# HT32F125x register map
File version: 1.1
This is the description for the Holtek HT32F125x
CPU: CM3 r2p0, little endian, no MPU, no FPU, 4 interrupt priority bits
Registers are 32-bit, read-write, reset 0x0 unless marked. A register's access mark holds for its fields unless they carry their own. Offsets are from the block's base; lines under a group give offsets from that group; [hi:lo] are bit positions; {n}, {i} and the like mark numbered series; 'fields as' and 'values as' point back to an identical list; <NAME> marks a mode.

## Memory map
0x40000000 USART size 0x1000
0x40004000 SPI size 0x1000
0x40010000 ADC size 0x1000
0x40018000 OPACMP size 0x1000
0x4001A000 GPIOA size 0x1000
0x4001B000 GPIOB size 0x1000
0x40022000 AFIO size 0x1000
0x40024000 EXTI size 0x1000
0x40048000 I2C size 0x1000
0x40068000 WDT size 0x1000
0x4006A000 RTC size 0x1000
0x4006A100 PWRCU size 0x1000
0x4006E000 GPTM0 size 0x1000
0x4006F000 GPTM1 size 0x1000
0x40080000 FMC size 0x1000
0x40088000 CKCU size 0x1000
0x40088100 RSTCU size 0x1000
0xE000E000 NVIC size 0x1000
0xE000E010 SysTick size 0x1000
0xE000ED10 SCB size 0x1000
0xE000ED28 Fault_Reports size 0x1000

## Interrupts
0 CKRDY (CKCU)
1 LVD (PWRCU)
2 BOD (PWRCU)
3 WDT
4 RTC
5 FMC
6 EVWUP (EXTI)
7 LPWUP (PWRCU)
{n+8} EXTI{n} (EXTI) (n=0..15)
24 COMP (OPACMP)
25 ADC
35 GPTM0
36 GPTM1
43 I2C
45 SPI
47 USART

## NVIC
Base 0xE000E000
0x04 ICTR
  [4:0] INTLINESNUM
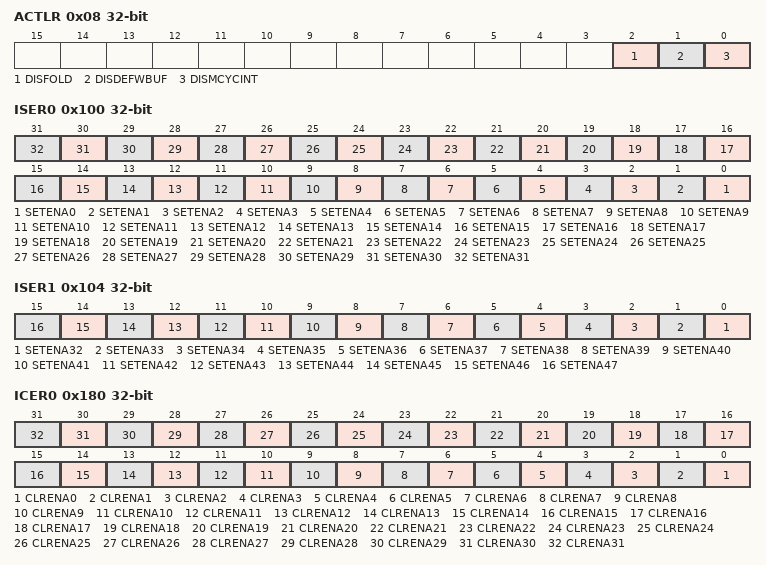
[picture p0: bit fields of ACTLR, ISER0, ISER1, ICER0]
0x08 ACTLR
  [2] DISFOLD, [1] DISDEFWBUF, [0] DISMCYCINT
0x100 ISER0
  [n] SETENA{n} (n=0..31)
0x104 ISER1
  [n-32] SETENA{n} (n=32..47)
0x180 ICER0
  [n] CLRENA{n} (n=0..31)
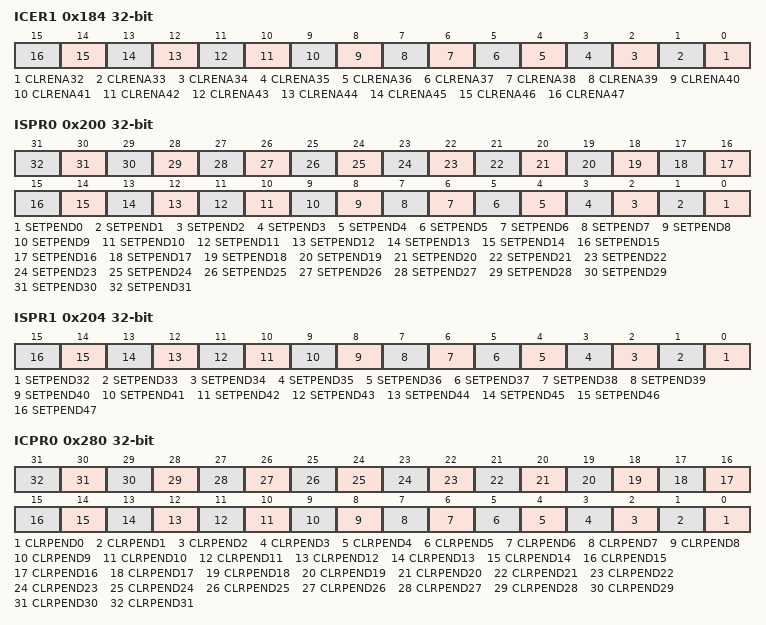
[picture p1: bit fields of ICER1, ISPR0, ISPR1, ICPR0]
0x184 ICER1
  [n-32] CLRENA{n} (n=32..47)
0x200 ISPR0
  [n] SETPEND{n} (n=0..31)
0x204 ISPR1
  [n-32] SETPEND{n} (n=32..47)
0x280 ICPR0
  [n] CLRPEND{n} (n=0..31)
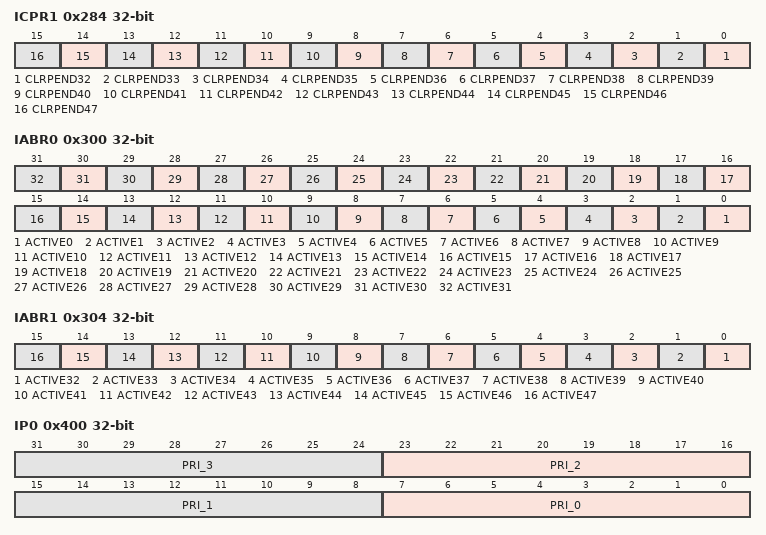
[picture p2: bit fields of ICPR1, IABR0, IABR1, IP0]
0x284 ICPR1
  [n-32] CLRPEND{n} (n=32..47)
0x300 IABR0
  [n] ACTIVE{n} (n=0..31)
0x304 IABR1
  [n-32] ACTIVE{n} (n=32..47)
0x400 IP0
  [8n+7:8n] PRI_{n} (n=0..3)
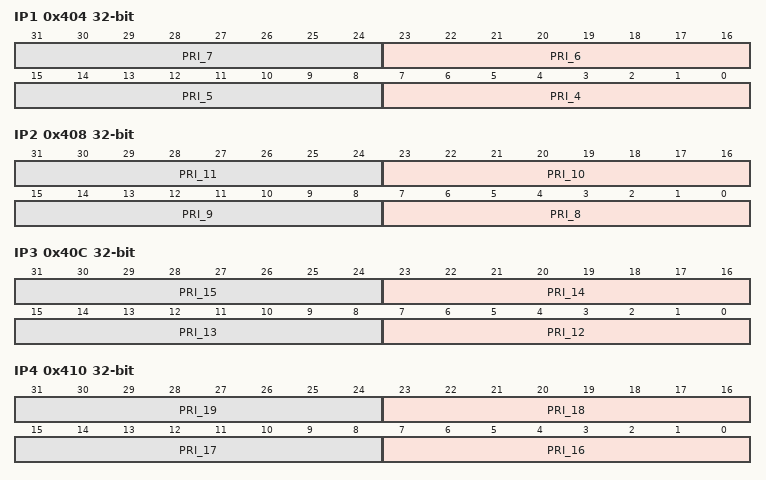
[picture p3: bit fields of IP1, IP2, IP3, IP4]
0x404 IP1
  [8n-25:8n-32] PRI_{n} (n=4..7)
0x408 IP2
  [8n-57:8n-64] PRI_{n} (n=8..11)
0x40C IP3
  [8n-89:8n-96] PRI_{n} (n=12..15)
0x410 IP4
  [8n-121:8n-128] PRI_{n} (n=16..19)
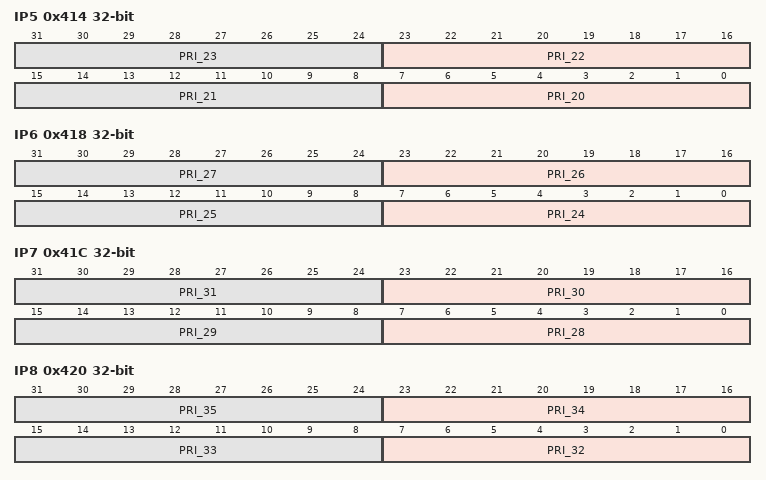
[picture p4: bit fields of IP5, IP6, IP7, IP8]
0x414 IP5
  [8n-153:8n-160] PRI_{n} (n=20..23)
0x418 IP6
  [8n-185:8n-192] PRI_{n} (n=24..27)
0x41C IP7
  [8n-217:8n-224] PRI_{n} (n=28..31)
0x420 IP8
  [8n-249:8n-256] PRI_{n} (n=32..35)
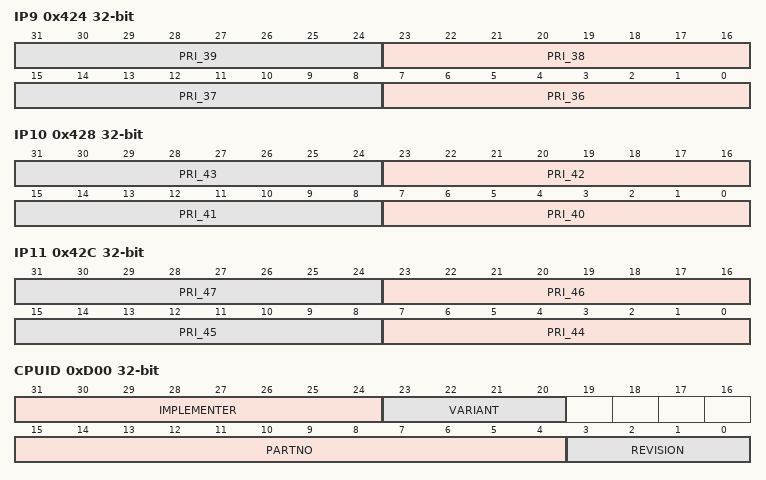
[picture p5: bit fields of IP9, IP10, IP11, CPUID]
0x424 IP9
  [8n-281:8n-288] PRI_{n} (n=36..39)
0x428 IP10
  [8n-313:8n-320] PRI_{n} (n=40..43)
0x42C IP11
  [8n-345:8n-352] PRI_{n} (n=44..47)
0xD00 CPUID
  [31:24] IMPLEMENTER, [23:20] VARIANT, [15:4] PARTNO, [3:0] REVISION
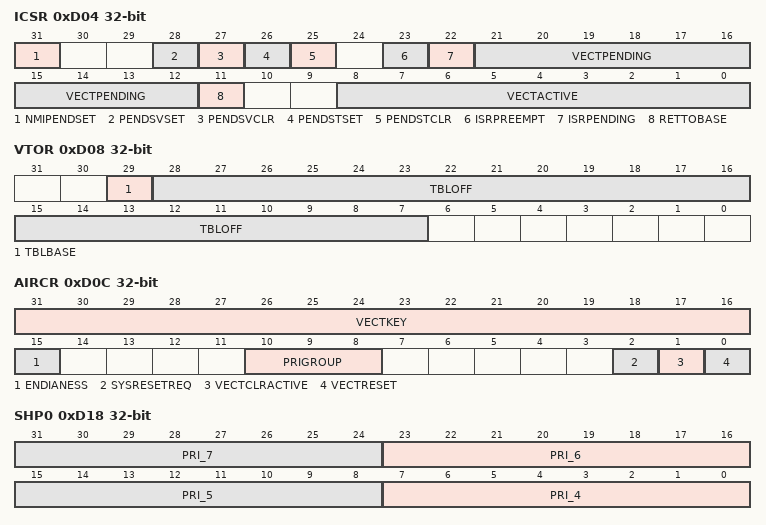
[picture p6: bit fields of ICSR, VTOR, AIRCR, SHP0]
0xD04 ICSR
  [31] NMIPENDSET, [28] PENDSVSET, [27] PENDSVCLR, [26] PENDSTSET, [25] PENDSTCLR, [23] ISRPREEMPT, [22] ISRPENDING, [21:12] VECTPENDING, [11] RETTOBASE, [8:0] VECTACTIVE
0xD08 VTOR
  [29] TBLBASE, [28:7] TBLOFF
0xD0C AIRCR
  [31:16] VECTKEY, [15] ENDIANESS, [10:8] PRIGROUP, [2] SYSRESETREQ, [1] VECTCLRACTIVE, [0] VECTRESET
0xD18 SHP0
  [8n-25:8n-32] PRI_{n} (n=4..7)
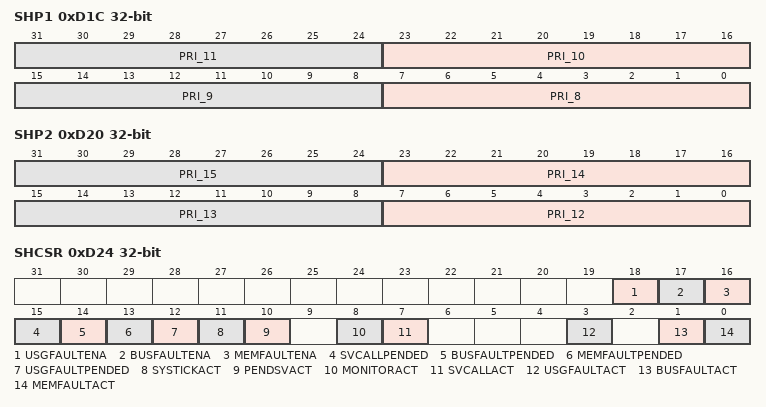
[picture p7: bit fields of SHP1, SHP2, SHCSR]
0xD1C SHP1
  [8n-57:8n-64] PRI_{n} (n=8..11)
0xD20 SHP2
  [8n-89:8n-96] PRI_{n} (n=12..15)
0xD24 SHCSR
  [18] USGFAULTENA, [17] BUSFAULTENA, [16] MEMFAULTENA, [15] SVCALLPENDED, [14] BUSFAULTPENDED, [13] MEMFAULTPENDED, [12] USGFAULTPENDED, [11] SYSTICKACT, [10] PENDSVACT, [8] MONITORACT, [7] SVCALLACT, [3] USGFAULTACT, [1] BUSFAULTACT, [0] MEMFAULTACT
0xF00 STIR
  [8:0] INTID

## SCB
Base 0xE000ED10
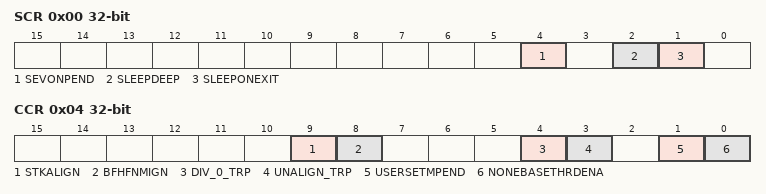
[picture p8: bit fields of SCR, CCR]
0x00 SCR
  [4] SEVONPEND, [2] SLEEPDEEP, [1] SLEEPONEXIT
0x04 CCR
  [9] STKALIGN, [8] BFHFNMIGN, [4] DIV_0_TRP, [3] UNALIGN_TRP, [1] USERSETMPEND, [0] NONEBASETHRDENA

## SysTick
Base 0xE000E010
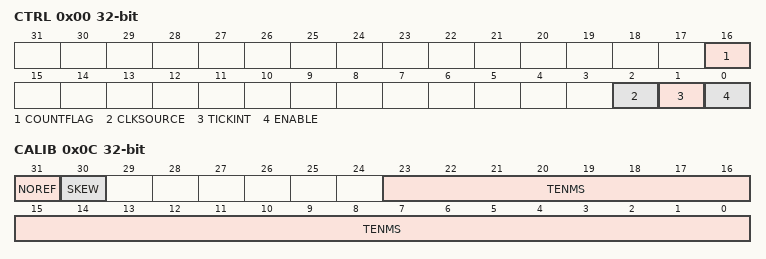
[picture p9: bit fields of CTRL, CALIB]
0x00 CTRL
  [16] COUNTFLAG, [2] CLKSOURCE, [1] TICKINT, [0] ENABLE
0x04 LOAD
  [23:0] RELOAD
0x08 VAL
  [23:0] CURRENT
0x0C CALIB
  [31] NOREF, [30] SKEW, [23:0] TENMS

## Fault_Reports
Base 0xE000ED28
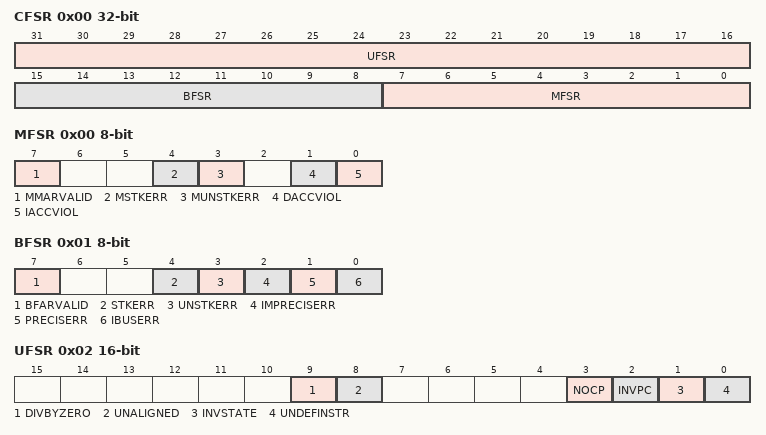
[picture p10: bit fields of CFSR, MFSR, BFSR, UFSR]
0x00 CFSR
  [31:16] UFSR, [15:8] BFSR, [7:0] MFSR
0x00 MFSR 8-bit (Fault_Reports view)
  [7] MMARVALID, [4] MSTKERR, [3] MUNSTKERR, [1] DACCVIOL, [0] IACCVIOL
0x01 BFSR 8-bit
  [7] BFARVALID, [4] STKERR, [3] UNSTKERR, [2] IMPRECISERR, [1] PRECISERR, [0] IBUSERR
0x02 UFSR 16-bit
  [9] DIVBYZERO, [8] UNALIGNED, [3] NOCP, [2] INVPC, [1] INVSTATE, [0] UNDEFINSTR
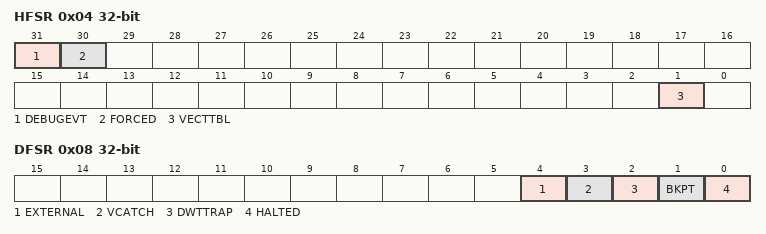
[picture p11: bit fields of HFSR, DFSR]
0x04 HFSR
  [31] DEBUGEVT, [30] FORCED, [1] VECTTBL
0x08 DFSR
  [4] EXTERNAL, [3] VCATCH, [2] DWTTRAP, [1] BKPT, [0] HALTED
0x0C MMFAR
  [31:0] ADDRESS
0x10 BFAR
  [31:0] ADDRESS
0x14 AFSR
  [31:0] IMPDEF

## Notices in the file
Copyright (C) 2010 ARM Limited. All rights reserved.
ARM Limited (ARM) is supplying this SVD description for use with Cortex-M3
processor based microcontrollers.  This file and or content can be freely
distributed within development tools that are supporting such ARM based
processors.
THIS SOFTWARE IS PROVIDED "AS IS".  NO WARRANTIES, WHETHER EXPRESS, IMPLIED
OR STATUTORY, INCLUDING, BUT NOT LIMITED TO, IMPLIED WARRANTIES OF
MERCHANTABILITY AND FITNESS FOR A PARTICULAR PURPOSE APPLY TO THIS SOFTWARE.
ARM SHALL NOT, IN ANY CIRCUMSTANCES, BE LIABLE FOR SPECIAL, INCIDENTAL, OR
CONSEQUENTIAL DAMAGES, FOR ANY REASON WHATSOEVER.
